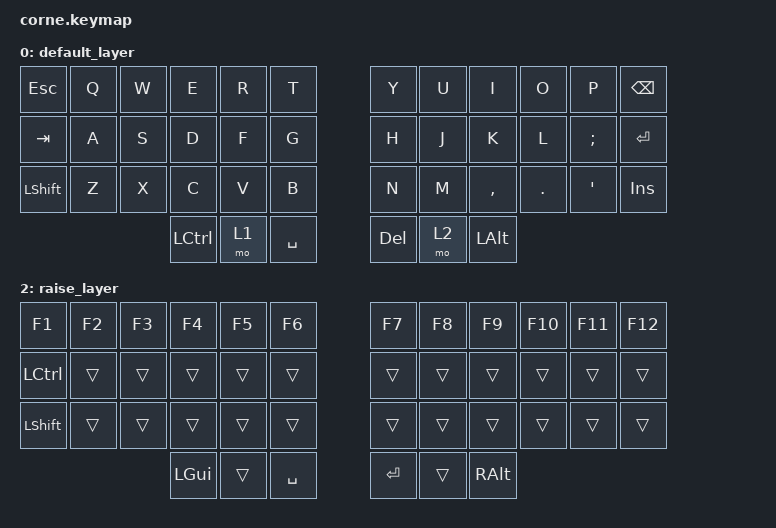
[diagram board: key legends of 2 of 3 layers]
/*
 * Copyright (c) 2020 The ZMK Contributors
 *
 * SPDX-License-Identifier: MIT
 */

#include <behaviors.dtsi>
#include <dt-bindings/zmk/bt.h>
#include <dt-bindings/zmk/keys.h>

/ {
    keymap {
        compatible = "zmk,keymap";

        default_layer {
            // -----------------------------------------------------------------------------------------
            // |  ESC |  Q  |  W  |  E  |  R  |  T  |   |  Y  |  U   |  I  |  O  |  P  | BSPC |
            // | TAB |  A  |  S  |  D  |  F  |  G  |   |  H  |  J   |  K  |  L  |  ;  |  ENTER   |
            // | SHFT |  Z  |  X  |  C  |  V  |  B  |   |  N  |  M   |  ,  |  .  |  '"  | INSERT  |
            //                    | CTRL | LWR | SPC |   | DEL | RSE  | ALT |

            bindings = <
&kp ESC    &kp Q  &kp W  &kp E      &kp R  &kp T        &kp Y    &kp U  &kp I      &kp O    &kp P     &kp BSPC
&kp TAB    &kp A  &kp S  &kp D      &kp F  &kp G        &kp H    &kp J  &kp K      &kp L    &kp SEMI  &kp RET
&kp LSHFT  &kp Z  &kp X  &kp C      &kp V  &kp B        &kp N    &kp M  &kp COMMA  &kp DOT  &kp SQT   &kp INSERT
                         &kp LCTRL  &mo 1  &kp SPACE    &kp DEL  &mo 2  &kp LALT
            >;
        };

        lower_layer {
            // -----------------------------------------------------------------------------------------
            // |  TAB |  1  |  2  |  3  |  4  |  5  |   |  6  |  7  |  8  |  9  |  0  | BSPC |
            // | BTCLR| BT1 | BT2 | BT3 | BT4 | BT5 |   | LFT | DWN |  UP | RGT |     |      |
            // | SHFT |     |     |     |     |     |   |     |     |     |     |     |      |
            //                    | GUI |     | SPC |   | ENT |     | ALT |

            bindings = <
&kp ESC          &kp N1  &kp N2  &kp N3  &none    &kp EQUAL    &kp MINUS  &bt TAB   &kp UP    &kp LEFT_BRACKET  &kp RIGHT_BRACKET  &kp BSPC
&kp PRINTSCREEN  &kp N4  &kp N5  &kp N6  &kp RET  &kp LSHFT    &kp N7     &kp LEFT  &kp DOWN  &kp RIGHT         &none              &none
&kp LSHFT        &kp N7  &kp N8  &kp N9  &kp N0   &none        &kp RWIN   &kp RALT
            >;
        };

        raise_layer {
            // -----------------------------------------------------------------------------------------
            // |  TAB |  !  |  @  |  #  |  $  |  %  |   |  ^  |  &  |  *  |  (  |  )  | BSPC |
            // | CTRL |     |     |     |     |     |   |  -  |  =  |  [  |  ]  |  \  |  `   |
            // | SHFT |     |     |     |     |     |   |  _  |  +  |  {  |  }  | "|" |  ~   |
            //                    | GUI |     | SPC |   | ENT |     | ALT |

            bindings = <
&kp F1     &kp F2  &kp F3  &kp F4    &kp F5  &kp F6       &kp F7   &kp F8  &kp F9    &kp F10  &kp F11  &kp F12
&kp LCTRL  &trans  &trans  &trans    &trans  &trans       &trans   &trans  &trans    &trans   &trans   &trans
&kp LSHFT  &trans  &trans  &trans    &trans  &trans       &trans   &trans  &trans    &trans   &trans   &trans
                           &kp LGUI  &trans  &kp SPACE    &kp RET  &trans  &kp RALT
            >;
        };
    };
};
